# D2522AA register map
Vendor: Dialog; Series: D2522AA; File version: 1.2
690
CPU: CM0 r1p0, little endian, MPU, FPU, 3 interrupt priority bits
Registers are 32-bit, read-write, reset 0x0 unless marked. A register's access mark holds for its fields unless they carry their own. Offsets are from the block's base; lines under a group give offsets from that group; [hi:lo] are bit positions; {n}, {i} and the like mark numbered series; 'fields as' and 'values as' point back to an identical list; <NAME> marks a mode.

## Memory map
0x100C0000 CACHE size 0x6C — CACHE registers
0x30020000 DW size 0x94 — DW registers
0x30030000 LCDC size 0x18C — LCDC registers
0x30040000 AES_HASH size 0x104 — AES_HASH registers
0x30070000 OTPC size 0x18 — OTPC registers
0x30090000 PATCH size 0xD0 — PATCH registers
0x34000000 QSPIC2 size 0x48 — QSPIC2 registers
0x38000000 QSPIC size 0xB4 — QSPIC registers
0x40000000 CMAC size 0x2110 — CMAC registers
0x40020000 RFCU size 0xB0 — RFCU registers
0x40020200 RFCU_POWER size 0x190 — RFCU_POWER registers
0x40021000 DEM size 0x70 — DEM registers
0x40022000 ADPLL size 0x98 — ADPLL registers
0x50000000 CRG_TOP size 0x100 — CRG_TOP registers
0x50000100 WAKEUP size 0x5C — WAKEUP registers
0x50000200 PDC size 0x98 — PDC registers
0x50000300 DCDC size 0x3C — DCDC registers
0x50000400 RTC size 0x98 — RTC registers
0x50000700 SYS_WDOG size 0x8 — SYS_WDOG registers
0x50010000 CRG_XTAL size 0x94 — CRG_XTAL registers
0x50010200 TIMER size 0x4C — TIMER registers
0x50010300 TIMER2 size 0x38 — TIMER2 registers
0x50010400 CMAC_TIMER_SLP size 0xC — CMAC_TIMER_SLP registers
0x50020000 UART size 0x100 — UART registers
0x50020100 UART2 size 0x100 — UART2 registers
0x50020200 UART3 size 0x100 — UART3 registers
0x50020300 SPI size 0xC — SPI registers
0x50020400 SPI2 size 0xC — SPI2 registers
0x50020600 I2C size 0x100 — I2C registers
0x50020700 I2C2 size 0x100 — I2C2 registers
0x50020800 SDADC size 0x1C — SDADC registers
0x50020900 CRG_COM size 0x10 — CRG_COM registers
0x50020A00 GPIO size 0x130 — GPIO registers
0x50020C00 SNC size 0x20 — SNC registers
0x50030500 PWMLED size 0x10 — PWMLED registers
0x50030600 APU size 0x114 — APU registers
0x50030900 GPADC size 0x1C — GPADC registers
0x50030A00 lra2522_busif_00 size 0x5C — lra2522_busif_00 registers
0x50030B00 ANAMISC size 0x1C — ANAMISC registers
0x50030C00 CRG_PER size 0x54 — CRG_PER registers
0x50030E00 SMOTOR size 0x84 — SMOTOR registers
0x50040000 USB size 0x1B0 — USB registers
0x50040200 CHIP_VERSION size 0x100 — CHIP_VERSION registers
0x50040300 GPREG size 0x1C — GPREG registers
0x50040400 CHARGER size 0x70 — CHARGER registers
0x50040500 CRG_SYS size 0x44 — CRG_SYS registers
0x50040600 RFMON size 0x18 — RFMON registers
0x50040800 DMA size 0x110 — DMA registers
0x50040A00 TIMER3 size 0x38 — TIMER3 registers
0x50040B00 TIMER4 size 0x38 — TIMER4 registers
0x50040C00 TRNG size 0xC — TRNG registers
0x50050000 MEMCTRL size 0x80 — MEMCTRL registers
0xE000E010 SysTick size 0x11 — Cortex M0 SysTick registers
0xE000E100 NVIC size 0x321 — Cortex M0 NVIC registers
0xE000ED00 SCB size 0x29 — Cortex M0 SCB registers

## SCB — Cortex M0 SCB registers
Base 0xE000ED00
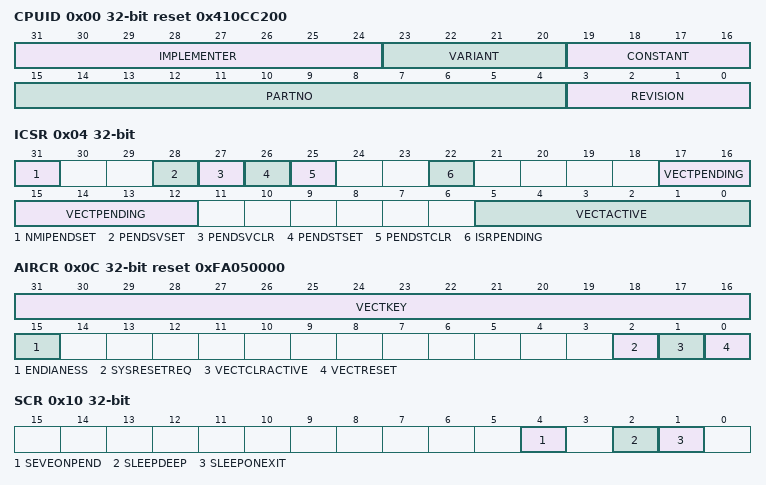
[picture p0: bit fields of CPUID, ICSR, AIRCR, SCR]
0x00 CPUID reset 0x410CC200 — CPUID base register
  [31:24] IMPLEMENTER ro — IMPLEMENTER[7:0] bits (Implementer code)
  [23:20] VARIANT ro — VARIANT[3:0] bits (Variant number)
  [19:16] CONSTANT ro — CONSTANT[3:0] bits (Reads as 0xF)
  [15:4] PARTNO ro — PARTNO[11:0] bits (Part number of the processor core)
  [3:0] REVISION ro — REVISION[3:0] bits (Revision number)
0x04 ICSR — Interrupt control and state register
  [31] NMIPENDSET — NMI set-pending bit
  [28] PENDSVSET — PendSV set-pending bit
  [27] PENDSVCLR — PendSV clear-pending bit
  [26] PENDSTSET — SysTick exception set-pending bit
  [25] PENDSTCLR — SysTick exception clear-pending bit
  [22] ISRPENDING — Interrupt pending flag, excluding NMI and Faults
  [17:12] VECTPENDING — VECTPENDING[5:0] bits (Pending vector)
  [5:0] VECTACTIVE — VECTACTIVE[5:0] bits (Active vector)
0x0C AIRCR ro reset 0xFA050000 — Application interrupt and reset control register
  [31:16] VECTKEY — VECTKEY[15:0] bits (Register key)
  [15] ENDIANESS — Data endianness bit
  [2] SYSRESETREQ — System reset request
  [1] VECTCLRACTIVE — Reserved for Debug use
  [0] VECTRESET — Reserved for Debug use
0x10 SCR — System control register
  [4] SEVEONPEND — Send event on pending bit
  [2] SLEEPDEEP — Controls whether the processor uses sleep or deep sleep
  [1] SLEEPONEXIT — Configures sleep-on-exit when returning from Handler mode to Thread mode
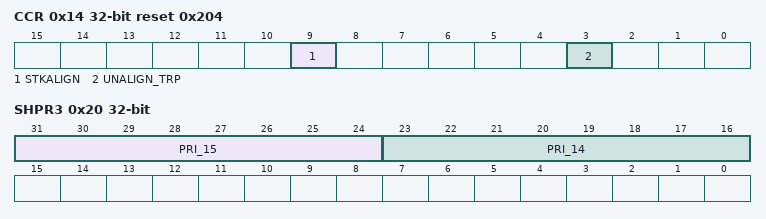
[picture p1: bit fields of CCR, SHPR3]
0x14 CCR reset 0x204 — Configuration and control register
  [9] STKALIGN — Configures stack alignment on exception entry
  [3] UNALIGN_TRP — Enables unaligned access traps
0x1C SHPR2 — System handler priority register 2
  [31:24] PRI_11 — PRI_11[7:0] bits (Priority of system handler 11, SVCall)
0x20 SHPR3 — System handler priority register 3
  [31:24] PRI_15 — PRI_15[7:0] bits (Priority of system handler 15, SysTick exception)
  [23:16] PRI_14 — PRI_14[7:0] bits (Priority of system handler 14, PendSV)

## Licence text in the file
Dialog GmbH (DLG) is supplying this software for use with Cortex-M processor based microcontroller, but can be equally used for other suitable processor architectures. This file can be freely distributed. Modifications to this file shall be clearly marked. . THIS SOFTWARE IS PROVIDED "AS IS". NO WARRANTIES, WHETHER EXPRESS, IMPLIED. OR STATUTORY, INCLUDING, BUT NOT LIMITED TO, IMPLIED WARRANTIES OF. MERCHANTABILITY AND FITNESS FOR A PARTICULAR PURPOSE APPLY TO THIS SOFTWARE. ARM SHALL NOT, IN ANY CIRCUMSTANCES, BE LIABLE FOR SPECIAL, INCIDENTAL, OR. CONSEQUENTIAL DAMAGES, FOR ANY REASON WHATSOEVER.

## Notices in the file
Copyright (C) 2017 Dialog Semiconductor.
This computer program includes Confidential, Proprietary Information
of Dialog Semiconductor. All Rights Reserved.
